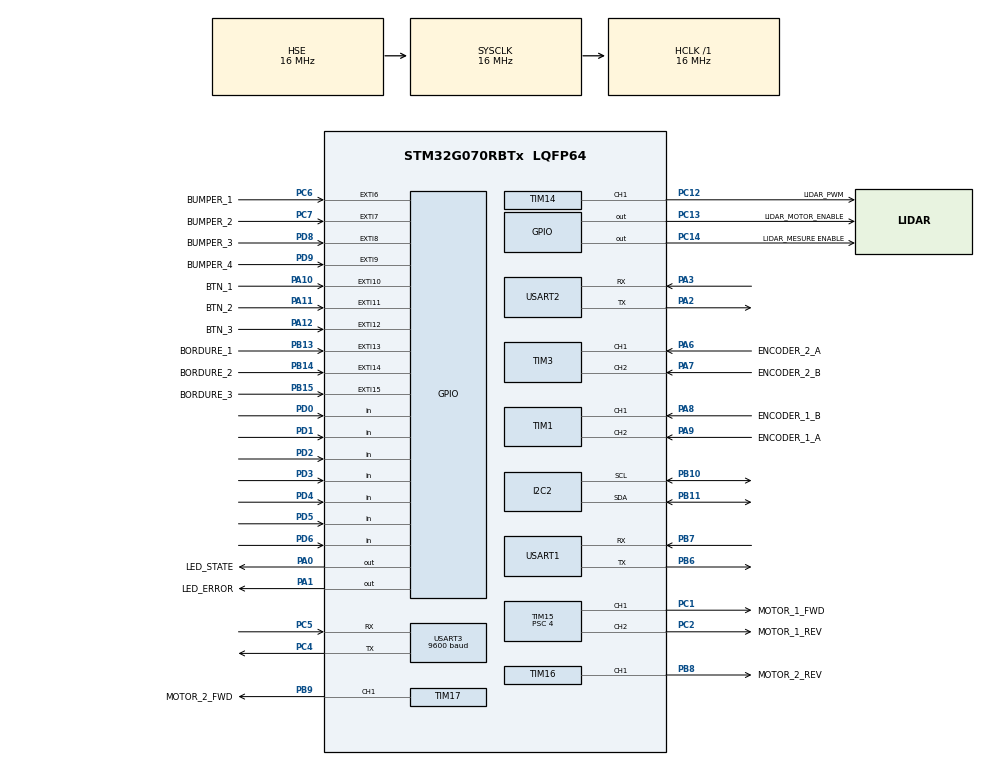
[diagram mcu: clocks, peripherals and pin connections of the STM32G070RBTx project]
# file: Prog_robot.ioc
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FREERTOS.Tasks01=defaultTask,0,128,StartDefaultTask,Default,NULL,Dynamic,NULL,NULL
FREERTOS.configTOTAL_HEAP_SIZE=30720
Mcu.Family=STM32G0
Mcu.Name=STM32G070RBTx
Mcu.Package=LQFP64
NVIC.EXTI4_15_IRQn=true\:3\:0\:false\:false\:true\:true\:true\:true\:true
NVIC.USART3_4_IRQn=true\:3\:0\:false\:false\:true\:true\:true\:true\:true
PA0.GPIO_Label=LED_STATE
PA0.Signal=GPIO_Output
PA1.GPIO_Label=LED_ERROR
PA1.Signal=GPIO_Output
PA10.GPIO_Label=BTN_1
PA10.Signal=GPXTI10
PA11\ [PA9].GPIO_Label=BTN_2
PA11\ [PA9].Signal=GPXTI11
PA12\ [PA10].GPIO_Label=BTN_3
PA12\ [PA10].Signal=GPXTI12
PA13.Mode=Serial_Wire
PA13.Signal=SYS_SWDIO
PA14-BOOT0.Mode=Serial_Wire
PA14-BOOT0.Signal=SYS_SWCLK
PA2.Mode=Asynchronous
PA2.Signal=USART2_TX
PA3.Mode=Asynchronous
PA3.Signal=USART2_RX
PA6.GPIO_Label=ENCODER_2_A
PA6.Signal=S_TIM3_CH1
PA7.GPIO_Label=ENCODER_2_B
PA7.Signal=S_TIM3_CH2
PA8.GPIO_Label=ENCODER_1_B
PA8.Signal=S_TIM1_CH1
PA9.GPIO_Label=ENCODER_1_A
PA9.Signal=S_TIM1_CH2
PB10.Mode=I2C
PB10.Signal=I2C2_SCL
PB11.Mode=I2C
PB11.Signal=I2C2_SDA
PB13.GPIO_Label=BORDURE_1
PB13.Signal=GPXTI13
PB14.GPIO_Label=BORDURE_2
PB14.Signal=GPXTI14
PB15.GPIO_Label=BORDURE_3
PB15.Signal=GPXTI15
PB6.Mode=Asynchronous
PB6.Signal=USART1_TX
PB7.Mode=Asynchronous
PB7.Signal=USART1_RX
PB8.GPIO_Label=MOTOR_2_REV
PB8.Signal=S_TIM16_CH1
PB9.GPIO_Label=MOTOR_2_FWD
PB9.Signal=S_TIM17_CH1
PC1.GPIO_Label=MOTOR_1_FWD
PC1.Signal=S_TIM15_CH1
PC12.GPIO_Label=LIDAR_PWM
PC12.Signal=S_TIM14_CH1
PC13.GPIO_Label=LIDAR_MOTOR_ENABLE
PC13.Signal=GPIO_Output
PC14-OSC32_IN\ (PC14).GPIO_Label=LIDAR_MESURE ENABLE
PC14-OSC32_IN\ (PC14).Signal=GPIO_Output
PC2.GPIO_Label=MOTOR_1_REV
PC2.Signal=S_TIM15_CH2
PC4.Mode=Asynchronous
PC4.Signal=USART3_TX
PC5.Mode=Asynchronous
PC5.Signal=USART3_RX
PC6.GPIO_Label=BUMPER_1
PC6.Signal=GPXTI6
PC7.GPIO_Label=BUMPER_2
PC7.Signal=GPXTI7
PD0.Signal=GPIO_Input
PD1.Signal=GPIO_Input
PD2.Signal=GPIO_Input
PD3.Signal=GPIO_Input
PD4.Signal=GPIO_Input
PD5.Signal=GPIO_Input
PD6.Signal=GPIO_Input
PD8.GPIO_Label=BUMPER_3
PD8.Signal=GPXTI8
PD9.GPIO_Label=BUMPER_4
PD9.Signal=GPXTI9
PF0-OSC_IN\ (PF0).Mode=HSE-External-Oscillator
PF0-OSC_IN\ (PF0).Signal=RCC_OSC_IN
PF1-OSC_OUT\ (PF1).Mode=HSE-External-Oscillator
PF1-OSC_OUT\ (PF1).Signal=RCC_OSC_OUT
ProjectManager.HeapSize=0x200
ProjectManager.StackSize=0x400
ProjectManager.TargetToolchain=STM32CubeIDE
RCC.ADCFreq_Value=16000000
RCC.AHBFreq_Value=16000000
RCC.CortexFreq_Value=16000000
RCC.EXTERNAL_CLOCK_VALUE=48000
RCC.HCLKFreq_Value=16000000
RCC.HSE_VALUE=16000000
RCC.HSI_VALUE=16000000
RCC.LSE_VALUE=32768
RCC.PLLSourceVirtual=RCC_PLLSOURCE_HSE
RCC.SYSCLKFreq_VALUE=16000000
RCC.SYSCLKSource=RCC_SYSCLKSOURCE_HSE
RCC.VCOOutputFreq_Value=128000000
SH.S_TIM14_CH1.0=TIM14_CH1,PWM Generation1 CH1
SH.S_TIM15_CH1.0=TIM15_CH1,PWM Generation1 CH1
SH.S_TIM15_CH2.0=TIM15_CH2,PWM Generation2 CH2
SH.S_TIM16_CH1.0=TIM16_CH1,PWM Generation1 CH1
SH.S_TIM17_CH1.0=TIM17_CH1,PWM Generation1 CH1
SH.S_TIM1_CH1.0=TIM1_CH1,Encoder_Interface
SH.S_TIM1_CH2.0=TIM1_CH2,Encoder_Interface
SH.S_TIM3_CH1.0=TIM3_CH1,Encoder_Interface
SH.S_TIM3_CH2.0=TIM3_CH2,Encoder_Interface
TIM14.Channel=TIM_CHANNEL_1
TIM15.AutoReloadPreload=TIM_AUTORELOAD_PRELOAD_ENABLE
TIM15.Channel-PWM\ Generation1\ CH1=TIM_CHANNEL_1
TIM15.Channel-PWM\ Generation2\ CH2=TIM_CHANNEL_2
TIM15.Period=127
TIM15.Prescaler=4
TIM16.Channel=TIM_CHANNEL_1
TIM16.Period=127
TIM16.Prescaler=4
TIM17.Channel=TIM_CHANNEL_1
TIM17.Period=127
TIM17.Prescaler=4
USART1.VirtualMode-Asynchronous=VM_ASYNC
USART2.VirtualMode-Asynchronous=VM_ASYNC
USART3.BaudRate=9600
USART3.VirtualMode-Asynchronous=VM_ASYNC
VP_FREERTOS_VS_CMSIS_V1.Mode=CMSIS_V1
VP_TIM14_VS_ClockSourceINT.Mode=Enable_Timer
VP_TIM16_VS_ClockSourceINT.Mode=Enable_Timer
VP_TIM17_VS_ClockSourceINT.Mode=Enable_Timer
VP_TIM6_VS_ClockSourceINT.Mode=Enable_Timer
VP_TIM7_VS_ClockSourceINT.Mode=Enable_Timer
board=custom

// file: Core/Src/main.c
/* USER CODE BEGIN Header */
/**
  ******************************************************************************
  * @file           : main.c
  * @brief          : Main program body
  ******************************************************************************
  * @attention
  *
  * Copyright (c) 2023 STMicroelectronics.
  * All rights reserved.
  *
  * This software is licensed under terms that can be found in the LICENSE file
  * in the root directory of this software component.
  * If no LICENSE file comes with this software, it is provided AS-IS.
  *
  ******************************************************************************
  */
/* USER CODE END Header */
#include "main.h"
#include "cmsis_os.h"
#include "i2c.h"
#include "tim.h"
#include "usart.h"
#include "gpio.h"

/* USER CODE BEGIN Includes */
#include "../../Drivers/HC05/tasks_HC05.h"
#include "../../Drivers/Motor/motor.h"

/* USER CODE END Includes */

/* USER CODE BEGIN PV */
extern driver_motor_t left_motor;
extern driver_motor_t right_motor;
/* USER CODE END PV */

void SystemClock_Config(void);
void MX_FREERTOS_Init(void);

int main(void)
{

  /* MCU Configuration--------------------------------------------------------*/

  /* Reset of all peripherals, Initializes the Flash interface and the Systick. */
  HAL_Init();

  /* Configure the system clock */
  SystemClock_Config();

  /* Initialize all configured peripherals */
  MX_GPIO_Init();
  MX_I2C2_Init();
  MX_TIM1_Init();
  MX_TIM3_Init();
  MX_TIM6_Init();
  MX_TIM7_Init();
  MX_TIM14_Init();
  MX_TIM15_Init();
  MX_TIM16_Init();
  MX_TIM17_Init();
  MX_USART1_UART_Init();
  MX_USART3_UART_Init();
  MX_USART2_UART_Init();
  /* USER CODE BEGIN 2 */
  // Create and start FreeRTOS tasks
  HAL_TIM_PWM_Start(left_motor.forward_htim,left_motor.forward_CHANNEL);
  HAL_TIM_PWM_Start(left_motor.reverse_htim,left_motor.reverse_CHANNEL);
  HAL_TIM_PWM_Start(right_motor.forward_htim,right_motor.forward_CHANNEL);
  HAL_TIM_PWM_Start(right_motor.reverse_htim,right_motor.reverse_CHANNEL);
  Start_HC05_Tasks();
  Start_motor_Tasks();
  // Start the scheduler
  vTaskStartScheduler();
  /* USER CODE END 2 */

  /* Call init function for freertos objects (in freertos.c) */
  MX_FREERTOS_Init();

  /* Start scheduler */
  osKernelStart();

  /* We should never get here as control is now taken by the scheduler */
  /* Infinite loop */
  while (1)
  {

  }
}

void SystemClock_Config(void)
{
  RCC_OscInitTypeDef RCC_OscInitStruct = {0};
  RCC_ClkInitTypeDef RCC_ClkInitStruct = {0};

  /** Configure the main internal regulator output voltage
  */
  HAL_PWREx_ControlVoltageScaling(PWR_REGULATOR_VOLTAGE_SCALE1);

  /** Initializes the RCC Oscillators according to the specified parameters
  * in the RCC_OscInitTypeDef structure.
  */
  RCC_OscInitStruct.OscillatorType = RCC_OSCILLATORTYPE_HSE;
  RCC_OscInitStruct.HSEState = RCC_HSE_ON;
  RCC_OscInitStruct.PLL.PLLState = RCC_PLL_NONE;
  if (HAL_RCC_OscConfig(&RCC_OscInitStruct) != HAL_OK)
  {
    Error_Handler();
  }

  /** Initializes the CPU, AHB and APB buses clocks
  */
  RCC_ClkInitStruct.ClockType = RCC_CLOCKTYPE_HCLK|RCC_CLOCKTYPE_SYSCLK
                              |RCC_CLOCKTYPE_PCLK1;
  RCC_ClkInitStruct.SYSCLKSource = RCC_SYSCLKSOURCE_HSE;
  RCC_ClkInitStruct.AHBCLKDivider = RCC_SYSCLK_DIV1;
  RCC_ClkInitStruct.APB1CLKDivider = RCC_HCLK_DIV1;

  if (HAL_RCC_ClockConfig(&RCC_ClkInitStruct, FLASH_LATENCY_0) != HAL_OK)
  {
    Error_Handler();
  }
}

void Error_Handler(void)
{
  __disable_irq();
  while (1)
  {
  }
}
